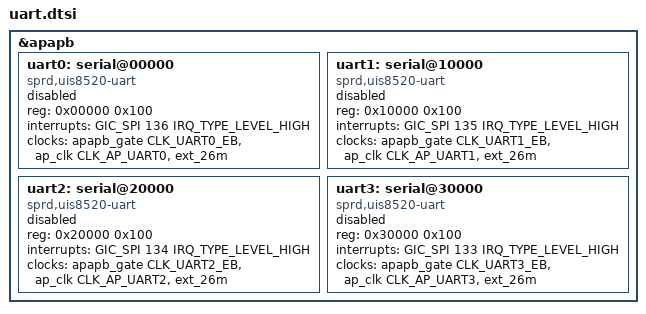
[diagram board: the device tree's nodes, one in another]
// SPDX-License-Identifier: (GPL-2.0+ OR MIT)
/*
 * Unisoc UART dts file
 *
 * Copyright (C) 2020, Unisoc Inc.
 *
 */

&apapb {
	uart0: serial@00000 {
		compatible = "sprd,uis8520-uart",
				"sprd,sc9836-uart";
		reg = <0x00000 0x100>;
		interrupts = <GIC_SPI 136 IRQ_TYPE_LEVEL_HIGH>;
		clock-names = "enable", "uart", "source";
		clocks = <&apapb_gate CLK_UART0_EB>,
			<&ap_clk CLK_AP_UART0>, <&ext_26m>;
		status = "disabled";
	};

	uart1: serial@10000 {
		compatible = "sprd,uis8520-uart",
				"sprd,sc9836-uart";
		reg = <0x10000 0x100>;
		interrupts = <GIC_SPI 135 IRQ_TYPE_LEVEL_HIGH>;
		clock-names = "enable", "uart", "source";
		clocks = <&apapb_gate CLK_UART1_EB>,
			<&ap_clk CLK_AP_UART1>, <&ext_26m>;
		status = "disabled";
	};

	uart2: serial@20000 {
		compatible = "sprd,uis8520-uart",
				"sprd,sc9836-uart";
		reg = <0x20000 0x100>;
		interrupts = <GIC_SPI 134 IRQ_TYPE_LEVEL_HIGH>;
		clock-names = "enable", "uart", "source";
		clocks = <&apapb_gate CLK_UART2_EB>,
			<&ap_clk CLK_AP_UART2>, <&ext_26m>;
		status = "disabled";
	};

	uart3: serial@30000 {
		compatible = "sprd,uis8520-uart",
				"sprd,sc9836-uart";
		reg = <0x30000 0x100>;
		interrupts = <GIC_SPI 133 IRQ_TYPE_LEVEL_HIGH>;
		clock-names = "enable", "uart", "source";
		clocks = <&apapb_gate CLK_UART3_EB>,
			<&ap_clk CLK_AP_UART3>, <&ext_26m>;
		status = "disabled";
	};
};
